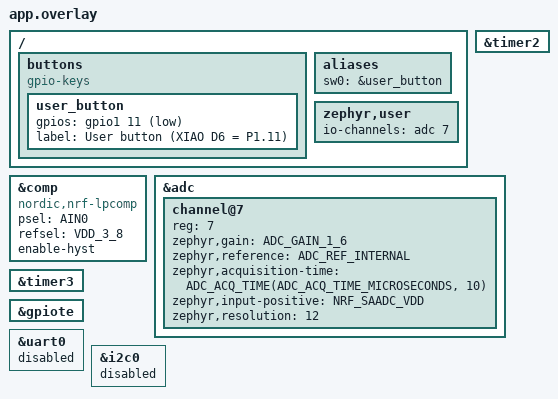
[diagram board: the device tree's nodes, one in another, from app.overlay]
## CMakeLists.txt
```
cmake_minimum_required(VERSION 3.20.0)

# Force-load our project overlay regardless of board target. Zephyr's
# auto-discovery of app.overlay doesn't fire reliably across every NCS
# version / board-target combo (in particular, board-qualified targets like
# xiao_ble/nrf52840/sense skip it), so we set it explicitly.
list(APPEND EXTRA_DTC_OVERLAY_FILE "${CMAKE_CURRENT_LIST_DIR}/app.overlay")

# Sense-only devicetree fragment. app.overlay is loaded for every target,
# so anything referencing nodes that exist only on the Sense variant (the
# LSM6DS3TR-C IMU and its regulator) has to be split out — otherwise the
# plain xiao_ble/nrf52840 build dies at DTS parse time on an undefined
# node label. See #75.
#
# Appended explicitly rather than named boards/xiao_ble_nrf52840_sense.overlay
# and left to auto-discovery, for the same reason app.overlay is force-loaded
# above: discovery has not been reliable here across NCS versions and
# board-qualified targets, and silently skipping this one would leave the IMU
# regulator drawing ~0.6-1.7 mA with a clean build log. The firmware-build CI
# job asserts against the generated devicetree that these nodes are actually
# disabled on a Sense build.
#
# BOARD is a cache variable set from the command line (-DBOARD=..., which is
# what `west build -b` passes), so it is already available here, before
# find_package(Zephyr).
if(BOARD MATCHES "sense")
	list(APPEND EXTRA_DTC_OVERLAY_FILE "${CMAKE_CURRENT_LIST_DIR}/overlays/sense.overlay")
endif()

find_package(Zephyr REQUIRED HINTS $ENV{ZEPHYR_BASE})
project(zigbee_energy_meter LANGUAGES C)

target_sources(app PRIVATE
	src/main.c
	src/battery_level.c
	src/button_action.c
	src/button_press_classifier.c
	src/calibration.c
	src/hw_pulse_counter.c
	src/led_controller.c
	src/led_priority.c
	src/metering_scale.c
	src/nvs_store.c
	src/persist_policy.c
	src/pulse_accumulator.c
	src/report_gate.c
	src/zigbee_app.c
)

target_include_directories(app PRIVATE src)
```

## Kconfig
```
mainmenu "Zigbee Energy Meter"

menu "LED signals (issue #33)"

config APP_BOOT_FLASH
	bool "Emit a 100 ms white flash on boot"
	default n
	help
	  When enabled, main() requests a single 100 ms all-LEDs-on
	  ("white") flash after led_controller_init() returns — the
	  same shape as the button-ack pattern from #28.

	  Silent-by-default preserves the "no LED except for user
	  gestures" contract on battery. Turn on via dev.conf for the
	  USB bench workflow.

config APP_REPORT_HEARTBEAT
	bool "Green flash on each 5-min metering report tick"
	default n
	help
	  When enabled, metering_report_work_handler requests a single
	  50 ms green flash on every 5-minute report cadence. Green is
	  chosen deliberately: red would imply fault, blue would collide
	  with the joining pattern; green reads as "healthy tick".

	  Silent by default so battery deployments don't emit a
	  visible pulse every 5 min. Turn on via dev.conf when watching
	  the reporting cadence on the bench.

endmenu

menu "Zigbee sleepy-ED behaviour (issue #8 blocker 1)"

config APP_ZIGBEE_SLEEPY_ED
	bool "Enable rx-off-when-idle sleepy end-device behaviour"
	default y
	help
	  Runtime toggle for zb_set_rx_on_when_idle(). CONFIG_ZIGBEE_ROLE_END_DEVICE
	  fixes the MAC-layer role; this flag controls whether the radio actually
	  sleeps between parent polls.

	  y (default) — sleepy: radio dark between polls. Required for the
	  battery target (average current in the µA range).

	  n — rx-on-when-idle: radio always live. Burns ~5 mA continuously,
	  but Z2M's ZDO interview (Read Basic.manufacturerName / .modelId)
	  cannot time out. Escape hatch if the sleepy + turbo-poll join
	  window is not enough to cover Z2M's read deadline in the field.

config APP_ZIGBEE_JOIN_TURBO_POLL_MS
	int "Turbo-poll window after successful join (ms)"
	default 30000
	depends on APP_ZIGBEE_SLEEPY_ED
	help
	  On ZB_BDB_SIGNAL_STEERING (status=RET_OK), start
	  zb_zdo_pim_start_turbo_poll_continuous for this many milliseconds.
	  During the window ZBOSS polls the parent every ~100 ms, which keeps
	  Z2M's interview reads responsive. When the timeout expires ZBOSS
	  automatically reverts to the Long Poll interval set below.

	  30 s covers the typical Z2M interview (~5-15 s) with generous
	  margin. Tighten once measurements say the interview always finishes
	  faster; loosen if a saturated coordinator makes reads slower.

config APP_ZIGBEE_WAKE_TURBO_POLL_MS
	int "Turbo-poll window opened by a short button press (ms)"
	default 30000
	depends on APP_ZIGBEE_SLEEPY_ED
	help
	  Length of the turbo-poll window that a short button press opens on
	  an already-joined device (issue #62). During the window ZBOSS polls
	  the parent every ~100 ms, so a Z2M write to a runtime-writable
	  attribute (imp_per_kwh, min_pulse_width_us) reaches the device well
	  inside Z2M's ~10 s ZCL deadline. In steady state the long poll below
	  is 60 s, so an unassisted write always times out.

	  Same 30 s default as the post-join window, for the same reason: it
	  is comfortably longer than a human takes to hit Save in the Z2M UI
	  after pressing the button, and it costs ~30 s of ~100 ms polling
	  only when the user asks for it — there is no steady-state cost.

config APP_ZIGBEE_CHECKIN_INTERVAL_S
	int "Poll Control check-in interval (seconds)"
	default 900
	depends on APP_ZIGBEE_SLEEPY_ED
	help
	  How often the Poll Control (0x0020) server sends a Check-In command
	  to its bound client (issue #62, option B). This is what makes a
	  write work with nobody at the device: zigbee-herdsman defaults a
	  genPollCtrl device's pendingRequestTimeout to the check-in interval,
	  so instead of failing at its 10 s ZCL deadline it *queues* the write
	  and flushes it when our Check-In arrives (it answers with
	  startFastPolling=1).

	  So this value is the worst-case latency for a scripted / unattended
	  write, and also the lifetime of Z2M's pending-request queue. 900 s
	  (15 min) trades a bounded wait against ~96 check-ins/day; each is one
	  short ZCL exchange, which is negligible against the sub-50 µA sleep
	  floor measured in #58. Raise it to spend less; lower it for snappier
	  unattended writes.

	  A short button press still opens an immediate window
	  (APP_ZIGBEE_WAKE_TURBO_POLL_MS) when someone is standing there — the
	  two mechanisms are complementary.

config APP_ZIGBEE_FAST_POLL_TIMEOUT_S
	int "Poll Control fast-poll timeout (seconds)"
	default 20
	depends on APP_ZIGBEE_SLEEPY_ED
	help
	  How long the device stays in fast poll after a Check-In Response that
	  requests it. Must be long enough for Z2M to drain its queued requests
	  for this device; 20 s clears a handful of attribute writes with
	  margin. Must be shorter than the check-in interval above.

config APP_ZIGBEE_LONG_POLL_INTERVAL_MS
	int "Long-poll interval after interview window (ms)"
	default 60000
	depends on APP_ZIGBEE_SLEEPY_ED
	help
	  Passed to zb_zdo_pim_set_long_poll_interval() after
	  ZB_BDB_SIGNAL_STEERING succeeds. Sets the steady-state parent-poll
	  cadence — every poll wakes the radio for a MAC ACK exchange
	  (~3 ms, ~10 mA), so this is a direct multiplier on average
	  current. 60 s picked as a conservative starting point: slow enough
	  to hit the µA-range sleep target, fast enough that any Z2M command
	  addressed to us has bounded downlink latency.

	  Not tunable below the ZBOSS floor ZB_PIM_MINIMUM_LONG_POLL_INTERVAL_IN_QS
	  (1 s). Not useful above ZB_PIM_MAXIMUM_LONG_POLL_INTERVAL (hours).

config APP_HW_PULSE_COUNTER
	bool "Bring up the LPCOMP → PPI → TIMER2 hardware pulse chain"
	default y
	help
	  When enabled (default), main() calls hw_pulse_counter_init() and the
	  sample loop reads hw_pulse_counter_read(). This is the production
	  configuration — the whole point of the device is to count meter
	  pulses in hardware while the CPU sleeps.

	  Turn OFF only as a diagnostic isolation: TIMER2 in counter mode is
	  clocked from PCLK16M (HFCLK-derived) and may be what's holding
	  HFCLK on in the joined-idle state, preventing the current from
	  dropping to the sub-mA System-ON deep-sleep floor. Layered overlay
	  for that isolation lives at `no-pulse.conf` — do NOT ship a build
	  with this off, the device won't count anything.

config APP_PULSE_MIN_WIDTH_US
	int "Minimum pulse width to count (µs, hardware-gated)"
	default 1000
	range 100 10000
	depends on APP_HW_PULSE_COUNTER
	help
	  Gate for the LPCOMP UP → PPI → TIMER2 chain and the D7 GPIOTE bench
	  chain. Both routes now feed TIMER3 which measures the pulse width
	  in real time; only pulses that hold above the reference for at
	  least this many microseconds are forwarded as TIMER2 COUNT.

	  Rationale for the default: torch flicker overcount at the bench
	  (`project_led_torch_flicker_pulse_count` memory, 2026-07-29) shows
	  low-frequency PWM cycles firing LPCOMP UP at rates the bench eye
	  reads as "steady on". A 1 ms floor rejects anything faster than
	  the slowest torch flicker rate we've measured while staying well
	  below any real electricity-meter LED (imp pulses are 20-100 ms).

	  Range mirrors the design doc: [100, 10000]. 100 µs is below the
	  LPCOMP settling and hysteresis roundtrip so anything shorter is
	  measurement noise; 10 ms is well below the shortest real meter LED
	  so a filter that high can't miss real pulses. NVS-backed runtime
	  override is planned (mirrors the divisor override from #48) but
	  not yet wired — this is the compile-time default and only knob.

	  Bench verification: `xiao-pulse.sh <ms>` at threshold ± some
	  margin. Sub-ms fractional-second precision on the Pi's userland
	  `sleep` is unreliable, so first bench passes use widths in the
	  10s of ms range for repeatability.

config APP_ZIGBEE_RX_IDLE_PROBE
	bool "Periodically log zb_get_rx_on_when_idle() over the log backend"
	default n
	help
	  Diagnostic probe for issue #51 / #8 blocker 1. When enabled, the
	  app logs zb_get_rx_on_when_idle() after zigbee_configure_sleepy_behavior,
	  on every ZB_BDB_SIGNAL_STEERING / ZB_BDB_SIGNAL_DEVICE_REBOOT, and on
	  a repeating 60 s tick from a delayable work item.

	  Off by default — production builds shouldn't emit these lines. Flip
	  on via rtt.conf (the RTT-over-SWD overlay) when hunting for whether
	  ZBOSS clobbers our FALSE setting post-join.

config APP_HW_HFCLK_PROBE
	bool "Periodically log HFCLKSTAT / HFCLKRUN + TIMER0-4 state"
	default n
	select APP_ZIGBEE_RX_IDLE_PROBE
	help
	  Diagnostic probe for the 2026-07-29 HFCLK-anchor hunt (#8). Piggy-
	  backs on the same signal-handler + 60 s-tick call sites as the
	  rx-idle probe. Logs two things per fire:

	  1. HFCLK status — nrf_clock_hf_is_running(HFXO),
	     NRF_CLOCK->HFCLKSTAT (state | src bits), NRF_CLOCK->HFCLKRUN.
	     Confirmed on 2026-07-29 that HFCLK is on via HFINT (not HFXO)
	     with HFCLKRUN=0 — so a peripheral is auto-requesting PCLK16M.

	  2. TIMER0-4 register snapshot — MODE, BITMODE, PRESCALER, INTENSET
	     for each of the five TIMER instances. A TIMER in MODE=0 (Timer,
	     not Counter) with non-zero INTENSET is armed and consuming
	     PCLK16M, which is the mechanism that keeps HFCLK on HFINT.
	     The 802.15.4 SL HPTIMER and MPSL both use TIMER instances.

	  Selects APP_ZIGBEE_RX_IDLE_PROBE — HFCLK/TIMER state is logged
	  from the same 60 s tick and signal-handler kick sites that the
	  rx-idle probe owns.

	  Off by default. Flip on via rtt.conf.

endmenu

menu "Metering calibration (issue #48)"

config APP_METERING_DEFAULT_IMP_PER_KWH
	int "Default imp/kWh (Metering-cluster Divisor) on cold boot"
	default 1000
	range 100 10000
	help
	  Value baked into the Metering cluster's Divisor attribute on a
	  cold boot (nothing persisted in NVS yet) or when the persisted
	  value has fallen out of the accepted range. Once a Z2M write
	  sets a new valid value, NVS wins — this default only re-appears
	  on a factory reset / NVS wipe.

	  Range enforced by src/calibration.c: [100, 10000]. Kept
	  identical here so the Kconfig menu itself rejects a nonsense
	  value at build time rather than deferring the reject to a
	  runtime "fallback to hardcoded 1000" that would surprise the
	  installer.

	  Design-doc default is 1000 (the row for "Zigbee model" in
	  seeed-studio-zigbee-energy-meter.md); keep it unless a
	  build ships against a known non-1000 meter.

endmenu

menu "Battery reporting (issue #8)"

config APP_BATTERY_REPORTING
	bool "Sample battery voltage and publish the Power Config cluster"
	default y
	select ADC
	help
	  Samples the SoC-internal VDD rail via SAADC on each 5-minute
	  report tick and publishes BatteryVoltage (0x0020) and
	  BatteryPercentageRemaining (0x0021) on the Power Configuration
	  cluster, which Z2M maps to the standard `battery` and `voltage`
	  exposes.

	  One conversion per report, not a sampling loop: the SAADC is
	  enabled for the ~10 us conversion and disabled again by the
	  driver's END IRQ. A peripheral left enabled requests PCLK16M and
	  pins HFCLK at ~1.5 mA, which is what the pre-#7 10 Hz loop cost.

	  Turning this off drops the cluster's values back to the 0xFF
	  "unknown" sentinel; the cluster itself is always declared so the
	  endpoint's simple descriptor doesn't change with a build option
	  (that would strand paired coordinators).

config APP_BATTERY_FULL_MV
	int "Battery voltage treated as 100 %"
	default 3000
	range 500 5000
	depends on APP_BATTERY_REPORTING
	help
	  2x AAA in series at ~1.5 V nominal each. Energizer Ultimate
	  Lithium (L92) sits near 1.5-1.6 V under light load for most of
	  its life, so 3000 mV is "as good as it gets" rather than the
	  3.6 V open-circuit reading of a fresh pack.

	  Must be greater than APP_BATTERY_EMPTY_MV; battery_level.c
	  returns 0 % for an inverted range rather than dividing by zero.

config APP_BATTERY_EMPTY_MV
	int "Battery voltage treated as 0 %"
	default 2000
	range 500 5000
	depends on APP_BATTERY_REPORTING
	help
	  2x 1.0 V, the usual lithium-AAA cutoff. The nRF52840 itself runs
	  down to 1.7 V, so the pack is the limit, not the SoC.

	  The map between these two endpoints is linear, which is a
	  deliberate simplification — a lithium AAA discharge curve is flat
	  enough that no simple curve is meaningfully better. Treat the
	  percentage as a "replace soon" indicator, not a fuel gauge.

endmenu

# Zephyr's Kconfig — pulls in board / driver / kernel options. Keep at
# the bottom so our project options land in the menu tree above the
# standard Zephyr tree, not buried under it.
source "Kconfig.zephyr"
```

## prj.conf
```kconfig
# Link the app at the DT-defined code partition offset (0x27000 on the XIAO)
# so it sits above the Adafruit UF2 bootloader's SoftDevice region.
CONFIG_USE_DT_CODE_PARTITION=y
CONFIG_BOOTLOADER_MCUBOOT=n

# NCS 2.9.2 xiao_ble board DT wires zephyr,console to a USB CDC-ACM UART, so
# the USB device stack must be enabled or the CDC-ACM driver's probe fails
# during kernel init and main() never runs. See CONTRIBUTING.md build gotchas.
CONFIG_SERIAL=y
CONFIG_USB_DEVICE_STACK=y
CONFIG_USB_DEVICE_PRODUCT="XIAO Zigbee Energy Meter"
CONFIG_USB_DEVICE_MANUFACTURER="kwood1992"
CONFIG_USB_DEVICE_VID=0x1915
CONFIG_USB_DEVICE_PID=0x520f
CONFIG_USB_CDC_ACM=y
CONFIG_UART_INTERRUPT_DRIVEN=y
CONFIG_UART_LINE_CTRL=y

CONFIG_CONSOLE=y
CONFIG_UART_CONSOLE=y

CONFIG_LOG=y
CONFIG_LOG_MODE_IMMEDIATE=y

CONFIG_GPIO=y

# --- Hardware pulse counting: LPCOMP + PPI + TIMER2 (issue #7) ---
#
# The chain lives in src/hw_pulse_counter.c: phototransistor → LPCOMP
# → PPI → TIMER2 (counter mode), plus a second PPI channel from GPIOTE
# on D7 → TIMER2 for the bench-inject path. All of it runs while the
# CPU is asleep in System-ON; the sample loop just calls
# nrfx_timer_capture() every wake to read the current count.
#
# NRFX_GPPI is the peripheral-agnostic PPI helper (works on both PPI
# and DPPI); on nRF52840 it auto-selects NRFX_PPI. NRFX_LPCOMP is
# gated on the `comp` node being switched to compat=nordic,nrf-lpcomp
# in app.overlay. NRFX_TIMER2 requires timer2's DT status=okay (TIMER1 is
# claimed by the 802.15.4 driver — see hw_pulse_counter.c).
# NRFX_GPIOTE0 is already pulled in by Zephyr's GPIO driver, listed
# here for documentation.
CONFIG_NRFX_LPCOMP=y
CONFIG_NRFX_GPPI=y
CONFIG_NRFX_TIMER2=y
# TIMER3 is the min-pulse-width filter's width-measure timer (#59).
# Timer mode, 1 MHz, 16-bit; CC[0] holds the threshold in µs. See
# hw_pulse_counter.c and docs/working/2026-07-29-min-pulse-width-spike.md.
CONFIG_NRFX_TIMER3=y
CONFIG_NRFX_GPIOTE0=y

# Disable the Zephyr `comparator` shim's auto-init of LPCOMP so we own
# the peripheral end-to-end from hw_pulse_counter.c. Without this the
# shim's SYS_INIT calls nrfx_lpcomp_init() first (with its own event
# handler) and our subsequent init returns NRFX_ERROR_ALREADY, leaving
# LPCOMP running under someone else's config.
CONFIG_COMPARATOR_NRF_LPCOMP=n

# NVS on the DT storage_partition (0x000ec000, 32 KB) — persists the pulse
# accumulator total so it survives resets. Policy lives in persist_policy.[ch].
CONFIG_FLASH=y
CONFIG_FLASH_MAP=y
CONFIG_FLASH_PAGE_LAYOUT=y
CONFIG_NVS=y

# --- Zigbee (ncs-zigbee R23 v1.3.0 add-on, ZBOSS R23 v4.2.2.3) ---
#
# R23 lives outside the NCS tree as an add-on module (pulled in by
# west.yml at modules/lib/ncs-zigbee). ZIGBEE_ADD_ON is the R23 flag —
# do NOT use the in-tree CONFIG_ZIGBEE (R22), which activates the older
# built-in stack under nrf/subsys/zigbee, pulls Partition Manager into
# the build unbidden, and requires a completely different pm_static.yml
# + CRYPTO + SETTINGS_NVS pile of setup to boot at all.
#
# Role: Sleepy End Device. ZBOSS runs on its own thread; the app talks
# to it via zigbee_app.[ch]. See docs/working/2026-07-22-zigbee-join.md
# for the join/reset flow and what needs bench verification.
CONFIG_ZIGBEE_ADD_ON=y
CONFIG_ZIGBEE_APP_UTILS=y
CONFIG_ZIGBEE_ROLE_END_DEVICE=y

# Scan all 2.4 GHz Zigbee channels (11–26) during steering instead
# of the default single channel 16. Without this, the device will
# only ever find coordinators on channel 16 — an easy silent
# failure mode when a coordinator ends up on 18, 20, 25 etc. after
# an interference scan. Multi-channel scan adds a few seconds to
# the first steering attempt; that's a one-time cost.
CONFIG_ZIGBEE_CHANNEL_SELECTION_MODE_MULTI=y

# Debug logging during first-time commissioning. app_utils at DBG
# emits every state transition (steering start, energy scan result,
# beacon received, association attempt) which we need to see when
# a join silently fails. 802.15.4 radio driver log shows TX/RX at
# the MAC layer — proves whether the radio is actually transmitting.
CONFIG_ZIGBEE_APP_UTILS_LOG_LEVEL_DBG=y

# Baseline runtime knobs the R23 samples all set. Mirror
# modules/lib/ncs-zigbee/samples/light_switch/prj.conf (the R23
# sleepy-ED reference). Without HEAP_MEM_POOL_SIZE, ZBOSS's dynamic
# allocations fault; without the bigger workqueue stack, Zigbee work
# items overflow it.
CONFIG_HEAP_MEM_POOL_SIZE=8192
CONFIG_SYSTEM_WORKQUEUE_STACK_SIZE=2048
# Human-readable ZBOSS error strings in the log — turns 0xffffffff-style
# opaque failure codes into "no such entity", "buffer full", etc.
# Costs a few KB of flash for the string table; worth it for debug builds.
CONFIG_ZIGBEE_ERROR_TO_STRING_ENABLED=y

# Disable IPv6/UDP so the Zigbee/802.15.4 stack doesn't pull in the
# wrong network layer. Zigbee is a 15.4-only device — no IP stack.
CONFIG_NET_IPV6=n
CONFIG_NET_IP_ADDR_CHECK=n
CONFIG_NET_UDP=n

# CONFIG_RESET_ON_FATAL_ERROR is intentionally NOT enabled during
# initial R23 bring-up. A fault loop under this option masks the
# Adafruit UF2 bootloader's double-tap-reset window — the board
# resets faster than the user can double-tap, and it looks bricked.
# Leave off until the R23 path boots cleanly on bench, then flip it
# on for the field build. See memory
# `project_reset_on_fatal_masks_bootloader.md`.

CONFIG_BUILD_OUTPUT_UF2=y
```

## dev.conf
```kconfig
# USB-dev overlay — layered on top of prj.conf with
#   west build … -- -DEXTRA_CONF_FILE=dev.conf
#
# Turns on the LED signals gated silent-by-default in prj.conf:
#   * 100 ms white boot flash
#   * 50 ms green flash on each 5-min metering report tick
#
# Not to be enabled for battery builds (defeats the "silent on battery"
# contract from #33).
CONFIG_APP_BOOT_FLASH=y
CONFIG_APP_REPORT_HEARTBEAT=y
```

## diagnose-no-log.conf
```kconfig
# Diagnostic overlay: does chatty immediate-mode logging prevent the
# ZBOSS scheduler from ever seeing a ≥20 ms idle window (and therefore
# from signalling ZB_COMMON_SIGNAL_CAN_SLEEP)?
#
# Isolates that hypothesis by stripping logs entirely at compile time.
# If the INA219 baseline drops from ~12 mA continuous to real sleepy-ED
# behaviour with this overlay, logging chatter is the root cause of the
# broken blocker #1 and a smaller fix (deferred mode + drop DBG levels)
# is warranted. If the baseline stays at ~12 mA, look elsewhere.
#
# Not intended to ship — the app has fatal-path LOG_ERRs that we want
# in prod builds.

CONFIG_LOG=n
```

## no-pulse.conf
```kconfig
# Isolation overlay: turn the hardware pulse chain off entirely.
#
# Purpose: measure whether TIMER2 in counter mode is anchoring HFCLK
# on and preventing the CPU from reaching System-ON deep sleep. If
# joined-idle current drops from ~1.6 mA to sub-mA with this applied,
# TIMER2 (or LPCOMP, or one of the PPI channels) is the anchor.
#
# Layer on top of rtt.conf:
#   west build … -- -DEXTRA_CONF_FILE="rtt.conf;no-pulse.conf"
#
# Do NOT ship a build with this — the device won't count anything.
# See docs/working/2026-07-29-blocker2-usb-off.md for the residual
# current investigation this overlay supports.

CONFIG_APP_HW_PULSE_COUNTER=n
```

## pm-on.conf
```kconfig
# Isolation overlay: enable Zephyr power management.
#
# Purpose: does CONFIG_PM=y allow the SoC power policy to actually
# gate HFCLK in idle? Without CONFIG_PM the default arch_idle() just
# calls WFI, which on nRF52 enters System-ON idle (HFCLK stays on ==
# ~1.6 mA). With CONFIG_PM the PM subsystem's policy_next_state hook
# can transition into deeper states where the clock controller
# actually releases HFCLK when no peripheral is requesting it.
#
# Bench-prep doc flagged this as risky "NCS 2.9.2 PM_DEVICE ↔ USB
# stack interactions" — but with rtt.conf's USB stack off, that
# concern doesn't apply.
#
# Layer on top of rtt.conf:
#   west build … -- -DEXTRA_CONF_FILE="rtt.conf;pm-on.conf"

CONFIG_PM=y
CONFIG_PM_DEVICE=y
```

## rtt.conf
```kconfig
# RTT-over-SWD logging overlay for battery / INA219-rig builds (issue #51).
#
# USB is physically unplugged on the current-measurement rig — CDC-ACM
# console is not reachable. This overlay swaps the log backend to Segger
# RTT so LOG_INF/LOG_WRN/LOG_ERR stream over the same 2-wire SWD path
# the Pi already uses for flashing, viewable via `tools/rtt-tail.sh`.
#
# Layered on prj.conf:
#   west build … -- -DEXTRA_CONF_FILE=rtt.conf
#
# Do NOT ship in the USB-dev build — USB-dev iteration wants CDC-ACM
# console. Overlay is diagnostic; keep the on-USB workflow unchanged.

# --- Segger RTT core -------------------------------------------------------
CONFIG_USE_SEGGER_RTT=y

# --- Log backends: RTT on, UART/CDC-ACM off --------------------------------
# LOG_BACKEND_UART=n stops the log subsystem from spraying to CDC-ACM in
# parallel with RTT. Without this, on a USB-attached build the log message
# would go out both channels; on the INA219 rig USB is unplugged so it'd
# only waste cycles.
CONFIG_LOG_BACKEND_RTT=y
CONFIG_LOG_BACKEND_UART=n

# printk() over RTT too, so early-boot printk-only diagnostics land in the
# same stream as the log subsystem output.
CONFIG_CONSOLE=y
CONFIG_RTT_CONSOLE=y
CONFIG_UART_CONSOLE=n

# --- RTT flow control ------------------------------------------------------
# DROP rather than BLOCK: on the INA219 rig the host may not always be
# attached (walk-away runs, host restart mid-capture). BLOCK would stall
# the CPU indefinitely waiting for buffer space, which would ruin the
# current measurement we're trying to take. DROP loses log lines instead
# — the RTT backend logs the drop count next time it drains.
CONFIG_LOG_BACKEND_RTT_MODE_DROP=y

# Default up-buffer is 1024 B. Bump modestly so the first-second flood of
# init logs (Zephyr banner, drivers, R23 init) doesn't drop on cold-boot
# before rtt-tail.sh's openocd finishes attaching.
CONFIG_SEGGER_RTT_BUFFER_SIZE_UP=4096

# --- USB device stack off (issue #8 blocker #2) ----------------------------
# On the battery / INA219 rig USB is physically unplugged. Leaving the
# USB device stack compiled in still initialises the USB PHY at boot
# (Zephyr's USB stack registers a SYS_INIT hook that calls usb_enable),
# and the USB PHY needs HFCLK running to service its 48 MHz clock —
# which prevents HFCLK auto-off during idle and pins average current
# at ~1.6 mA (CPU System-ON idle, HFCLK on) instead of the sub-mA
# System-ON deep sleep the sleepy-ED path should reach.
#
# Turning the stack off compiles the whole USB init block in main.c
# out (guarded by IS_ENABLED(CONFIG_USB_DEVICE_STACK)) and drops the
# 5 s wait_for_host_dtr_or_timeout() from boot as a bonus.
#
# Do NOT copy this into dev.conf — the USB-dev workflow needs CDC-ACM
# for console iteration.
CONFIG_USB_DEVICE_STACK=n
CONFIG_USB_CDC_ACM=n

# --- Diagnostic app probes -------------------------------------------------
# The whole point of building with rtt.conf right now is to answer the
# #8-blocker-1 question: does zb_get_rx_on_when_idle() stay FALSE after
# join, or does ZBOSS clobber it? Turn the probe on by default whenever
# we're building for RTT.
CONFIG_APP_ZIGBEE_RX_IDLE_PROBE=y

# HFCLK-anchor hunt probe for the 1.65 mA residual (issue #8, follow-up
# to 2026-07-29-hfclk-anchor-hunt.md). Logs HFCLKSTAT / HFCLKRUN and
# nrf_clock_hf_is_running() on the same tick+signal cadence as the
# rx-idle probe. Answers whether HFCLK is actually running in the
# settled post-join state.
CONFIG_APP_HW_HFCLK_PROBE=y
```

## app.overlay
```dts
/*
 * Project overlay — always applied regardless of board target. Forced into
 * the DTS pipeline via EXTRA_DTC_OVERLAY_FILE in CMakeLists.txt.
 *
 * Wires the hardware pulse-counting chain that runs during System-ON sleep
 * (see src/hw_pulse_counter.c and issue #7):
 *
 *   - `comp` re-configured as an LPCOMP (Low-Power COMParator) with the
 *     phototransistor on AIN0 (P0.02 = XIAO A0) as its input and VDD*3/8
 *     (~1.24 V @ 3.3 V VDD, 1.125 V @ 3.0 V VDD) as its reference. HYST is
 *     enabled to reject jitter near the threshold with no CPU wake — see
 *     hw_pulse_counter.c for the noise-filter reasoning.
 *   - `timer2` brought up so hw_pulse_counter can drive it in counter mode
 *     via nrfx. (TIMER0 is the radio driver's; TIMER1 is the 802.15.4
 *     driver's — enabling either fails Kconfig or races the stack. TIMER2
 *     is the lowest-numbered free instance.)
 *   - `gpiote` brought up so the bench D7 falling-edge inject-path
 *     (Pi → xiao-pulse.sh) can be routed to the same TIMER via PPI. Zephyr's
 *     GPIO driver on nRF also uses this instance, which is fine — the nrfx
 *     GPIOTE allocator coordinates channel ownership between the two.
 *
 * Retained:
 *   - User button on XIAO D6 (P1.11), still driven by Zephyr GPIO for
 *     Zigbee join / factory-reset. Bench rig: Pi BCM17 → D6.
 *
 * Re-added for #8:
 *   - The `zephyr,user` ADC channel + `&adc` block, for battery voltage.
 *     This is NOT the 10 Hz sample loop that was removed after #7 — it is
 *     a single one-shot conversion on the 5-minute report tick. The
 *     distinction matters for power: Zephyr's SAADC driver enables the
 *     peripheral in adc_context_start_sampling() and disables it again in
 *     the END IRQ (zephyr/drivers/adc/adc_nrfx_saadc.c), so SAADC.ENABLE
 *     is non-zero only for the ~10 µs conversion. A peripheral left
 *     enabled requests PCLK16M and pins HFCLK — that was the ~1.5 mA
 *     anchor UARTE0/TWIM0 caused below, and it is exactly what a sampling
 *     *loop* would reintroduce.
 *
 * Removed (relative to pre-#7):
 *   - The `sw1` / `pulse_input` gpio-keys entry — D7 is no longer a Zephyr
 *     GPIO consumer; hw_pulse_counter drives it directly through nrfx
 *     GPIOTE. Pin assignment (P1.12) is documented in that C file.
 */

#include <zephyr/dt-bindings/gpio/gpio.h>
#include <zephyr/dt-bindings/adc/adc.h>

/ {
	buttons {
		compatible = "gpio-keys";

		user_button: user_button {
			gpios = <&gpio1 11 (GPIO_ACTIVE_LOW | GPIO_PULL_UP)>;
			label = "User button (XIAO D6 = P1.11)";
		};
	};

	aliases {
		sw0 = &user_button;
	};

	/*
	 * Battery-voltage sense channel (#8). Consumed via
	 * ADC_DT_SPEC_GET(DT_PATH(zephyr_user)) in zigbee_app.c.
	 */
	zephyr,user {
		io-channels = <&adc 7>;
	};
};

&comp {
	status = "okay";
	compatible = "nordic,nrf-lpcomp";
	psel = "AIN0";
	refsel = "VDD_3_8";
	enable-hyst;
};

&timer2 {
	status = "okay";
};

/*
 * SAADC for battery voltage (#8), per the design doc's "sample battery
 * (SAADC on VDD)".
 *
 * Input is the SoC-internal VDD tap (NRF_SAADC_VDD), not an AIN pin:
 *   - no pin to wire, no divider, no enable GPIO, so nothing to conflict
 *     with the LPCOMP already sitting on AIN0;
 *   - the XIAO's own battery divider (P0.31 + P0.14 enable) would burn
 *     current through the divider whenever it is enabled and differs
 *     between XIAO variants.
 *
 * Gain 1/6 against the 0.6 V internal reference gives a 3.6 V full scale,
 * which covers a fresh 2x AAA pack (~3.2 V) and the 3.3 V bench rail with
 * headroom. Channel index 7 is arbitrary — VDD is not pin-mapped.
 *
 * NOTE: this reads the rail the SoC is actually running from. On the
 * bench that is the Pi 3V3 supply, so battery percentage will read 100 %
 * until the board is on cells.
 */
&adc {
	status = "okay";
	#address-cells = <1>;
	#size-cells = <0>;

	channel@7 {
		reg = <7>;
		zephyr,gain = "ADC_GAIN_1_6";
		zephyr,reference = "ADC_REF_INTERNAL";
		zephyr,acquisition-time = <ADC_ACQ_TIME(ADC_ACQ_TIME_MICROSECONDS, 10)>;
		zephyr,input-positive = <NRF_SAADC_VDD>;
		zephyr,resolution = <12>;
	};
};

/*
 * TIMER3: width-measure gate for the min-pulse-width filter (issue #59,
 * see docs/working/2026-07-29-min-pulse-width-spike.md). Timer mode,
 * 1 MHz, 16-bit; CC[0] holds the threshold in µs, CC0_STOP short freezes
 * the timer once the threshold is reached so PCLK16M is only requested
 * while a pulse is in flight. TIMER0/1/2 are already claimed
 * (radio / 802.15.4 / this project's counter); TIMER3 is the next free
 * instance.
 */
&timer3 {
	status = "okay";
};

&gpiote {
	status = "okay";
};

/*
 * The XIAO Sense's IMU regulator disable used to live here. It moved to
 * overlays/sense.overlay, which CMakeLists.txt appends only for board
 * targets ending in "sense".
 *
 * It had to move: &lsm6ds3tr_c and the two regulator nodes exist only in
 * the Sense variant's board DT, so referencing them from this file — which
 * is force-loaded for every target — made the plain xiao_ble/nrf52840
 * build fail at DTS parse time. See #75.
 *
 * Everything below this point applies to both variants.
 */

/*
 * Kill the two on-board EasyDMA peripherals that were the real ~1.5 mA
 * anchor. When their ENABLE register is non-zero, UARTE and TWIM instances
 * request PCLK16M, which auto-starts HFCLK on HFINT and pins the SoC at
 * the ~1.6 mA "System-ON idle, HFCLK on" datasheet floor even with the
 * CPU in WFE.
 *
 * SWD peripheral snapshot showed UARTE0.ENABLE=8 and TWIM0.ENABLE=6 on
 * every build to date. Neither is used by this app on rtt.conf builds:
 *
 * - UART0 was left enabled by the board DTS as the default console. In
 *   this build CONFIG_UART_CONSOLE=n / CONFIG_LOG_BACKEND_UART=n / no
 *   shell — nothing needs it. Disable at the DT level so Zephyr never
 *   probes the driver and never touches ENABLE.
 *
 * - I2C0 hosted the LSM6DS3TR-C IMU (disabled above). With the child
 *   node status=disabled, Zephyr still probes the parent bus driver
 *   which enables the peripheral. Explicit disable at the parent level
 *   is what actually stops the ENABLE write.
 *
 * If dev.conf ever needs I2C or UART back (bench sensor, uart console),
 * re-enable via the dev.conf-specific overlay path instead of undoing
 * this — the battery build must ship with both off.
 */
&uart0 {
	status = "disabled";
};

&i2c0 {
	status = "disabled";
};
```

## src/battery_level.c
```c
#include "battery_level.h"

uint8_t battery_level_percent(uint16_t mv, uint16_t empty_mv, uint16_t full_mv)
{
	if (full_mv <= empty_mv) {
		/* Misconfigured range. Report empty rather than trapping;
		 * see the header note on why this path must not fault.
		 */
		return 0U;
	}
	if (mv <= empty_mv) {
		return 0U;
	}
	if (mv >= full_mv) {
		return 100U;
	}

	uint32_t span = (uint32_t)full_mv - (uint32_t)empty_mv;
	uint32_t above = (uint32_t)mv - (uint32_t)empty_mv;

	/* Round to nearest: (above * 100 + span/2) / span. Max intermediate
	 * is 65535 * 100, comfortably inside u32.
	 */
	return (uint8_t)(((above * 100U) + (span / 2U)) / span);
}

uint8_t battery_level_zcl_percentage(uint8_t percent)
{
	if (percent >= 100U) {
		return 200U;
	}
	return (uint8_t)(percent * 2U);
}

uint8_t battery_level_zcl_voltage(uint16_t mv)
{
	uint32_t units = ((uint32_t)mv + 50U) / 100U;  /* round to nearest */

	if (units > 254U) {
		return 254U;
	}
	return (uint8_t)units;
}
```

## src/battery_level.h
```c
#ifndef BATTERY_LEVEL_H
#define BATTERY_LEVEL_H 1

#include <stdint.h>

/*
 * Battery state-of-charge mapping and ZCL Power Configuration (0x0001)
 * wire encodings — issue #8.
 *
 * Pure integer logic, no Zephyr dependency, so it is host-tested in
 * tests/test_battery_level.c. The SAADC read that feeds it lives in
 * zigbee_app.c, which is the part that can only be verified on-bench.
 *
 * Why linear: 2x AAA lithium (Energizer Ultimate L92) holds a famously
 * flat discharge curve, so a voltage-to-percentage map is approximate at
 * best whatever shape you choose. A linear map between two Kconfig-tunable
 * endpoints is honest about that and is trivially re-tunable from bench
 * data without a table rebuild. Do not read the percentage as accurate
 * mid-life; it is a "replace soon" indicator.
 */

/* ZCL "unknown / invalid" for both BatteryVoltage (0x0020) and
 * BatteryPercentageRemaining (0x0021). Reported when the SAADC read
 * fails, so Z2M shows nothing rather than a plausible-looking zero.
 */
#define BATTERY_LEVEL_ZCL_UNKNOWN 0xFFU

/*
 * Linear map from millivolts to 0-100 %, clamped at both ends and
 * rounded to nearest. Returns 0 for a degenerate range (empty >= full)
 * rather than dividing by zero — this runs on the 5-minute report path
 * and a fault here would drop the device off the network.
 */
uint8_t battery_level_percent(uint16_t mv, uint16_t empty_mv, uint16_t full_mv);

/*
 * ZCL BatteryPercentageRemaining (0x0021): units of 0.5 %, so the wire
 * value is 0-200 and Z2M halves it again. Clamped to 200 — 0xFF is the
 * "unknown" sentinel and 201-254 are undefined.
 */
uint8_t battery_level_zcl_percentage(uint8_t percent);

/*
 * ZCL BatteryVoltage (0x0020): units of 100 mV, rounded to nearest.
 * Saturates at 254 so an out-of-range reading can never be mistaken for
 * the 0xFF "unknown" sentinel.
 */
uint8_t battery_level_zcl_voltage(uint16_t mv);

#endif /* BATTERY_LEVEL_H */
```

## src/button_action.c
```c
#include "button_action.h"

enum button_action button_action_for_press(enum button_press_kind kind,
					  bool joined)
{
	switch (kind) {
	case BUTTON_PRESS_SHORT:
		return joined ? BUTTON_ACTION_WAKE : BUTTON_ACTION_JOIN;
	case BUTTON_PRESS_LONG:
		return BUTTON_ACTION_FACTORY_RESET;
	case BUTTON_PRESS_NEITHER:
	default:
		/* Unknown classifications fall through to NONE rather than
		 * to anything that changes device state.
		 */
		return BUTTON_ACTION_NONE;
	}
}
```

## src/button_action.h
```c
#ifndef BUTTON_ACTION_H
#define BUTTON_ACTION_H

#include <stdbool.h>

#include "button_press_classifier.h"

/*
 * Routes a classified button press to the action it should take, given
 * the current join state. Split from button_press_classifier because
 * "how long was it held" and "what should that mean right now" are two
 * separate decisions — the classifier is state-free, this is not.
 *
 * The short press is overloaded on purpose (issue #62):
 *
 *   not joined → JOIN. The original behaviour: kick off network
 *                steering so the user can pair the device.
 *   joined     → WAKE. Re-steering an already-joined device is a no-op
 *                at best, so the press instead opens a turbo-poll
 *                window. Without it, a Z2M write to a runtime-writable
 *                attribute (imp_per_kwh, min_pulse_width_us) has to
 *                wait out the 60 s steady-state long poll and blows
 *                past Z2M's 10 s ZCL deadline.
 *
 * Long press is unconditional — a device the user believes is stuck is
 * exactly when factory reset has to work regardless of join state.
 */

enum button_action {
	BUTTON_ACTION_NONE = 0,
	BUTTON_ACTION_JOIN,
	BUTTON_ACTION_WAKE,
	BUTTON_ACTION_FACTORY_RESET,
};

enum button_action button_action_for_press(enum button_press_kind kind,
					   bool joined);

#endif
```

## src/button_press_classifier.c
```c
#include "button_press_classifier.h"

void button_press_classifier_init(struct button_press_classifier *c,
				  uint32_t short_max_ms,
				  uint32_t long_min_ms)
{
	c->short_max_ms = short_max_ms;
	c->long_min_ms = long_min_ms;
}

enum button_press_kind button_press_classifier_classify(
	const struct button_press_classifier *c,
	uint32_t duration_ms)
{
	if (duration_ms == 0) {
		return BUTTON_PRESS_NEITHER;
	}
	if (duration_ms < c->short_max_ms) {
		return BUTTON_PRESS_SHORT;
	}
	if (duration_ms >= c->long_min_ms) {
		return BUTTON_PRESS_LONG;
	}
	return BUTTON_PRESS_NEITHER;
}
```

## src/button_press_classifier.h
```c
#ifndef BUTTON_PRESS_CLASSIFIER_H
#define BUTTON_PRESS_CLASSIFIER_H

#include <stdint.h>

/*
 * Turns a "held for N ms" duration into a discrete short-press / long-press /
 * ignored classification. Kept as a pure-logic helper so the thresholds and
 * edge-case handling can be host-tested without Zephyr's GPIO stack.
 *
 * The gap between short_max_ms and long_min_ms is deliberate — the design
 * doc calls out short = <1 s (join) and long = >3 s (factory reset). Presses
 * that land between 1 and 3 s classify as NEITHER, so an accidental
 * mid-length release neither joins a network nor factory-resets the device.
 */

enum button_press_kind {
	BUTTON_PRESS_NEITHER = 0,
	BUTTON_PRESS_SHORT,
	BUTTON_PRESS_LONG,
};

struct button_press_classifier {
	uint32_t short_max_ms;
	uint32_t long_min_ms;
};

void button_press_classifier_init(struct button_press_classifier *c,
				  uint32_t short_max_ms,
				  uint32_t long_min_ms);

enum button_press_kind button_press_classifier_classify(
	const struct button_press_classifier *c,
	uint32_t duration_ms);

#endif
```

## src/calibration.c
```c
#include "calibration.h"

bool calibration_is_valid_imp_per_kwh(uint32_t imp_per_kwh)
{
	return imp_per_kwh >= CALIBRATION_IMP_PER_KWH_MIN &&
	       imp_per_kwh <= CALIBRATION_IMP_PER_KWH_MAX;
}

bool calibration_is_valid_pulse_min_width_us(uint32_t min_width_us)
{
	return min_width_us >= CALIBRATION_PULSE_MIN_WIDTH_US_MIN &&
	       min_width_us <= CALIBRATION_PULSE_MIN_WIDTH_US_MAX;
}
```

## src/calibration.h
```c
#ifndef CALIBRATION_H
#define CALIBRATION_H

#include <stdbool.h>
#include <stdint.h>

/*
 * Pure validation for the runtime-configurable imp/kWh calibration
 * (issue #48). The Metering cluster's Divisor attribute IS the imp/kWh
 * value directly (Multiplier is pinned to 1), so a Divisor write from
 * Z2M gets validated through here before it lands in NVS.
 *
 * Range picked defensively: 100 imp/kWh at the low end (below that, a
 * single pulse represents >0.01 kWh — coarse enough to make the
 * accumulator jumpy in Z2M), 10000 at the high end (well above any
 * residential meter I've seen documented; the u24 wire ceiling of
 * 16777215 sits far above this and isn't the tightening constraint).
 * Anything outside is a typo; reject rather than silently clamp so a
 * Z2M attribute write returns INVALID_VALUE and the user sees the
 * error rather than getting the wrong scale.
 */
#define CALIBRATION_IMP_PER_KWH_MIN 100U
#define CALIBRATION_IMP_PER_KWH_MAX 10000U

bool calibration_is_valid_imp_per_kwh(uint32_t imp_per_kwh);

/*
 * Validation for the min-pulse-width filter threshold (issue #59). Range
 * mirrors CONFIG_APP_PULSE_MIN_WIDTH_US:
 *
 * - 100 µs floor: below LPCOMP settling + hysteresis roundtrip; anything
 *   shorter is measurement noise.
 * - 10 000 µs ceiling: well below the shortest real electricity-meter
 *   LED (imp pulses are 20-100 ms), so any legal filter can't miss real
 *   pulses.
 *
 * Same reject-rather-than-clamp policy as imp/kWh — out-of-range writes
 * return INVALID_VALUE to Z2M so the installer sees the error.
 */
#define CALIBRATION_PULSE_MIN_WIDTH_US_MIN 100U
#define CALIBRATION_PULSE_MIN_WIDTH_US_MAX 10000U

bool calibration_is_valid_pulse_min_width_us(uint32_t min_width_us);

#endif
```

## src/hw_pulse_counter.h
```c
#ifndef HW_PULSE_COUNTER_H
#define HW_PULSE_COUNTER_H

#include <stdint.h>

/* Bring up the LPCOMP → PPI → TIMER2 hardware pulse chain plus a second
 * PPI branch from GPIOTE(D7) → TIMER2 that preserves the tools/xiao-pulse.sh
 * bench-inject workflow. After a successful call the counter is running and
 * every phototransistor rising edge (LPCOMP UP) OR bench D7 falling edge
 * bumps the same 32-bit hardware register with no CPU involvement.
 *
 * Returns 0 on success or a negative errno on driver init failure.
 */
int hw_pulse_counter_init(void);

/* Snapshot the TIMER2 counter register via a CAPTURE task. Cheap (a
 * handful of register writes/reads), safe to call from any thread, and
 * does not stop or clear the counter. Wraps at 2^32 pulses — the software
 * accumulator handles that in the same way it already handled the atomic_t
 * source before this module existed.
 */
uint32_t hw_pulse_counter_read(void);

/* Retune the min-pulse-width filter's TIMER3 CC[0] threshold live (issue
 * #59 impl-2). Callable from any thread. Caller MUST validate the value
 * via calibration_is_valid_pulse_min_width_us() first — this function
 * does no range check and will program whatever fits in TIMER3.CC[0].
 * Persistence to NVS is the caller's responsibility; this only touches
 * the running CC register.
 */
void hw_pulse_counter_set_min_width_us(uint32_t min_width_us);

#endif
```

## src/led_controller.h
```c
#ifndef LED_CONTROLLER_H
#define LED_CONTROLLER_H

#include <stdint.h>

#include "led_priority.h"

/*
 * Onboard RGB LED controller for the XIAO nRF52840. Owns led0 (red),
 * led1 (green), and led2 (blue) via their DT aliases, and mediates every
 * LED-driving code path through the priority table declared in
 * led_priority.h.
 *
 * Foundation slice of issue #28: only LED_PATTERN_BUTTON_ACK is wired to
 * a concrete renderer (100 ms all-LEDs-on flash) in this file. The other
 * slots are dispatchable — a caller can request them, priority-arbitration
 * runs — but nothing renders yet. Follow-up issues #29, #30, #32, #33
 * land the remaining renderers (join lifecycle, long-press hold, fatal
 * loops, boot / heartbeat flashes).
 *
 * The existing main.c LED users (heartbeat toggle, boot blink, erase
 * confirm) still poke led0 directly through their own gpio_dt_spec and
 * are NOT migrated in this slice — they land in follow-ups. That means a
 * button-ack flash briefly displaces whatever colour the heartbeat had on
 * red; acceptable per the issue's explicit "unchanged in this issue"
 * carve-out.
 */

int led_controller_init(void);

void led_request(enum led_pattern_id pattern, enum led_priority prio);
void led_cancel(enum led_pattern_id pattern);

/*
 * Request the top-priority fatal-error pattern with `flash_count` red
 * flashes per 5-second cycle at ~10% duty (#32). Clamped to 1..5.
 *
 * Flash-count → failure-site mapping (kept in main.c's fatal branches;
 * updating this table means updating the mapping there too):
 *   1 = CDC-ACM device_not_ready
 *   2 = usb_enable failed
 *   3 = user_button_configure failed
 *   4 = hw_pulse_counter_init failed
 *   5 = user_button_arm_irq failed
 *
 * After 10 minutes of continuous flashing, the pattern collapses to a
 * single 100 ms flash every 10 s — a broken field device with fresh
 * batteries needs the failure indicator to survive long enough to be
 * noticed on a maintenance visit weeks later, and 10% duty over
 * fortnights burns the pack.
 */
void led_request_fatal(uint32_t flash_count);

#endif /* LED_CONTROLLER_H */
```
